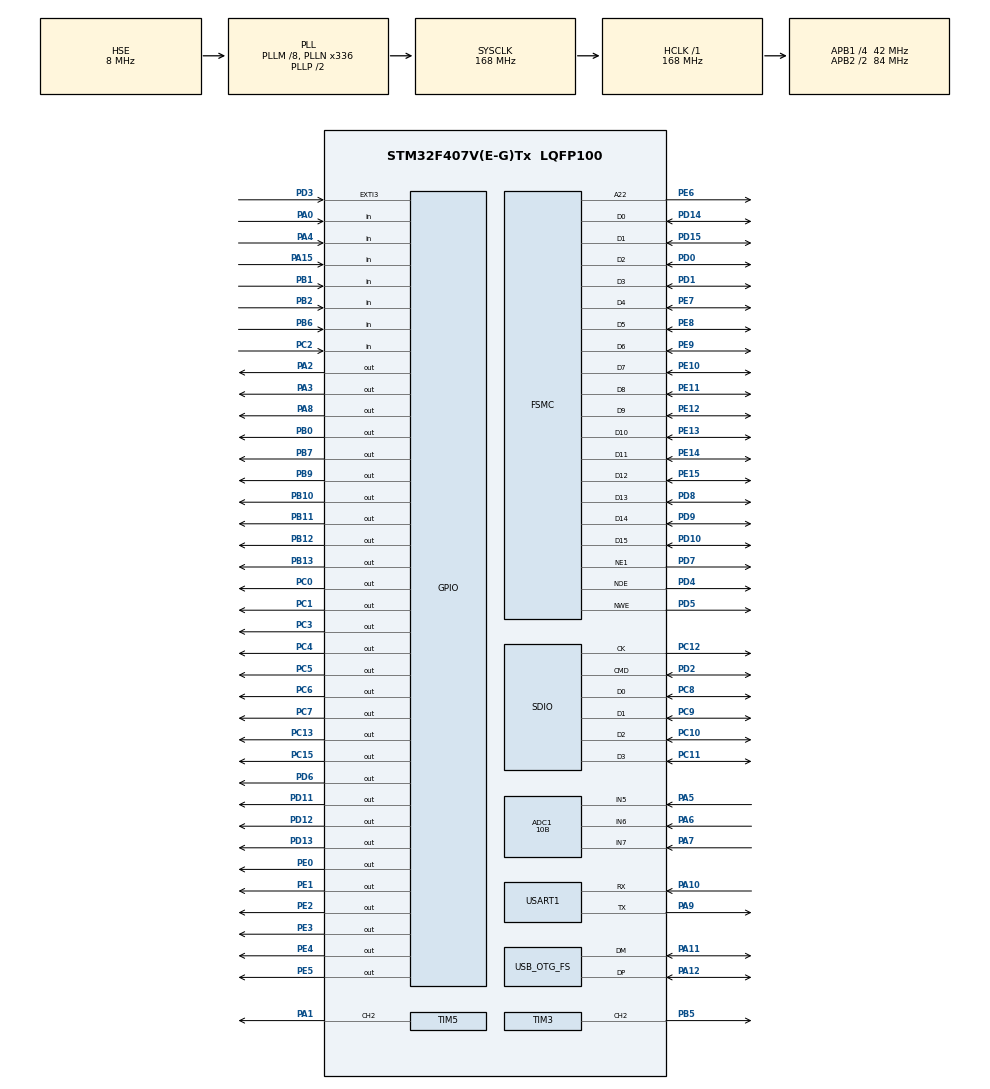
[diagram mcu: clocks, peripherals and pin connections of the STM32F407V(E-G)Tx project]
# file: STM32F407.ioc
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ADC1.Channel-0\#ChannelRegularConversion=ADC_CHANNEL_7
ADC1.ClockPrescaler=ADC_CLOCK_SYNC_PCLK_DIV4
ADC1.ContinuousConvMode=DISABLE
ADC1.DMAContinuousRequests=DISABLE
ADC1.DataAlign=ADC_DATAALIGN_RIGHT
ADC1.DiscontinuousConvMode=DISABLE
ADC1.EOCSelection=ADC_EOC_SINGLE_CONV
ADC1.EnableAnalogWatchDog=false
ADC1.ExternalTrigConvEdge=ADC_EXTERNALTRIGCONVEDGE_NONE
ADC1.InjNumberOfConversion=0
ADC1.NbrOfConversion=1
ADC1.NbrOfConversionFlag=1
ADC1.Rank-0\#ChannelRegularConversion=1
ADC1.Resolution=ADC_RESOLUTION_10B
ADC1.SamplingTime-0\#ChannelRegularConversion=ADC_SAMPLETIME_3CYCLES
ADC1.ScanConvMode=ENABLE
ADC1.master=1
Dma.Request0=USART1_RX
Dma.Request1=USART1_TX
Dma.Request2=SDIO_RX
Dma.Request3=SDIO_TX
Dma.SDIO_RX.2.Direction=DMA_PERIPH_TO_MEMORY
Dma.SDIO_RX.2.FIFOMode=DMA_FIFOMODE_ENABLE
Dma.SDIO_RX.2.FIFOThreshold=DMA_FIFO_THRESHOLD_FULL
Dma.SDIO_RX.2.Instance=DMA2_Stream3
Dma.SDIO_RX.2.MemBurst=DMA_MBURST_INC4
Dma.SDIO_RX.2.MemDataAlignment=DMA_MDATAALIGN_WORD
Dma.SDIO_RX.2.MemInc=DMA_MINC_ENABLE
Dma.SDIO_RX.2.Mode=DMA_PFCTRL
Dma.SDIO_RX.2.PeriphBurst=DMA_PBURST_INC4
Dma.SDIO_RX.2.PeriphDataAlignment=DMA_PDATAALIGN_WORD
Dma.SDIO_RX.2.PeriphInc=DMA_PINC_DISABLE
Dma.SDIO_RX.2.Priority=DMA_PRIORITY_LOW
Dma.SDIO_TX.3.Direction=DMA_MEMORY_TO_PERIPH
Dma.SDIO_TX.3.FIFOMode=DMA_FIFOMODE_ENABLE
Dma.SDIO_TX.3.FIFOThreshold=DMA_FIFO_THRESHOLD_FULL
Dma.SDIO_TX.3.Instance=DMA2_Stream6
Dma.SDIO_TX.3.MemBurst=DMA_MBURST_INC4
Dma.SDIO_TX.3.MemDataAlignment=DMA_MDATAALIGN_WORD
Dma.SDIO_TX.3.MemInc=DMA_MINC_ENABLE
Dma.SDIO_TX.3.Mode=DMA_PFCTRL
Dma.SDIO_TX.3.PeriphBurst=DMA_PBURST_INC4
Dma.SDIO_TX.3.PeriphDataAlignment=DMA_PDATAALIGN_WORD
Dma.SDIO_TX.3.PeriphInc=DMA_PINC_DISABLE
Dma.SDIO_TX.3.Priority=DMA_PRIORITY_LOW
Dma.USART1_RX.0.Direction=DMA_PERIPH_TO_MEMORY
Dma.USART1_RX.0.FIFOMode=DMA_FIFOMODE_DISABLE
Dma.USART1_RX.0.Instance=DMA2_Stream5
Dma.USART1_RX.0.MemDataAlignment=DMA_MDATAALIGN_BYTE
Dma.USART1_RX.0.MemInc=DMA_MINC_ENABLE
Dma.USART1_RX.0.Mode=DMA_CIRCULAR
Dma.USART1_RX.0.PeriphDataAlignment=DMA_PDATAALIGN_BYTE
Dma.USART1_RX.0.PeriphInc=DMA_PINC_DISABLE
Dma.USART1_RX.0.Priority=DMA_PRIORITY_LOW
Dma.USART1_TX.1.Direction=DMA_MEMORY_TO_PERIPH
Dma.USART1_TX.1.FIFOMode=DMA_FIFOMODE_DISABLE
Dma.USART1_TX.1.Instance=DMA2_Stream7
Dma.USART1_TX.1.MemDataAlignment=DMA_MDATAALIGN_BYTE
Dma.USART1_TX.1.MemInc=DMA_MINC_ENABLE
Dma.USART1_TX.1.Mode=DMA_CIRCULAR
Dma.USART1_TX.1.PeriphDataAlignment=DMA_PDATAALIGN_BYTE
Dma.USART1_TX.1.PeriphInc=DMA_PINC_DISABLE
Dma.USART1_TX.1.Priority=DMA_PRIORITY_LOW
FATFS.BSP.number=1
FATFS._CODE_PAGE=936
FATFS._FS_LOCK=16
FATFS._MAX_LFN=128
FATFS._MAX_SS=512
FATFS._USE_LFN=3
FATFS._USE_TRIM=0
FATFS0.BSP.STBoard=false
FATFS0.BSP.api=UnknownBspDriver
FATFS0.BSP.i2caddr=0
FATFS0.BSP.i2creg=0
FATFS0.BSP.instance=PB6
FATFS0.BSP.ip=GPIO
FATFS0.BSP.mode=Input
FATFS0.BSP.name=Detect_SDIO
FATFS0.BSP.solution=PB6
FREERTOS.CountingSemaphores01=GUISendSem,2,Dynamic,NULL;GUIWaitSem,2,Dynamic,NULL;ReadUdiskSem,2,Dynamic,NULL;ReceiveUartCmd,2,Dynamic,NULL
FREERTOS.HEAP_NUMBER=4
FREERTOS.INCLUDE_uxTaskGetStackHighWaterMark=1
FREERTOS.Queues01=GcodeCommand,32,uint32_t,0,Dynamic,NULL,NULL
FREERTOS.Tasks01=InitTask,3,1024,InitTask_OS,Default,NULL,Dynamic,NULL,NULL;RefDataTask,2,1024,RefDataTask_OS,Default,NULL,Dynamic,NULL,NULL;ReadUdiskTask,2,1024,ReadUdiskTask_OS,Default,NULL,Dynamic,NULL,NULL;PrintTask,2,1024,PrintTask_OS,Default,NULL,Dynamic,NULL,NULL;GUITask,0,1024,GUITask_OS,Default,NULL,Dynamic,NULL,NULL;RespondGUITask,0,1024,RespondGUITask_OS,Default,NULL,Dynamic,NULL,NULL
FREERTOS.configGENERATE_RUN_TIME_STATS=0
FREERTOS.configLIBRARY_MAX_SYSCALL_INTERRUPT_PRIORITY=5
FREERTOS.configMAX_PRIORITIES=7
FREERTOS.configMINIMAL_STACK_SIZE=128
FREERTOS.configTOTAL_HEAP_SIZE=32768
FREERTOS.configUSE_COUNTING_SEMAPHORES=1
FREERTOS.configUSE_RECURSIVE_MUTEXES=1
FREERTOS.configUSE_STATS_FORMATTING_FUNCTIONS=0
FREERTOS.configUSE_TICKLESS_IDLE=0
FREERTOS.configUSE_TRACE_FACILITY=1
FSMC.BusTurnAroundDuration1=0
FSMC.DataSetupTime1=60
FSMC.ExtendedAddressSetupTime1=9
FSMC.ExtendedBusTurnAroundDuration1=0
FSMC.ExtendedDataSetupTime1=8
FSMC.ExtendedMode1=FSMC_EXTENDED_MODE_ENABLE
IWDG.Prescaler=IWDG_PRESCALER_64
IWDG.Reload=3125
Mcu.Family=STM32F4
Mcu.Name=STM32F407V(E-G)Tx
Mcu.Package=LQFP100
NVIC.ADC_IRQn=true\:6\:0\:true\:false\:true\:true\:true
NVIC.DMA2_Stream3_IRQn=true\:5\:0\:true\:false\:true\:true\:true
NVIC.DMA2_Stream5_IRQn=true\:7\:0\:true\:false\:true\:true\:true
NVIC.DMA2_Stream6_IRQn=true\:5\:0\:true\:false\:true\:true\:true
NVIC.DMA2_Stream7_IRQn=true\:7\:0\:true\:false\:true\:true\:true
NVIC.EXTI3_IRQn=true\:5\:0\:true\:false\:true\:true\:true
NVIC.OTG_FS_IRQn=true\:5\:0\:true\:false\:true\:true\:true
NVIC.PriorityGroup=NVIC_PRIORITYGROUP_4
NVIC.SDIO_IRQn=true\:5\:0\:true\:false\:true\:true\:true
NVIC.TIM1_UP_TIM10_IRQn=true\:0\:0\:false\:false\:true\:false\:true
NVIC.TIM2_IRQn=true\:7\:0\:true\:false\:true\:true\:true
NVIC.TIM3_IRQn=true\:7\:0\:true\:false\:true\:true\:true
NVIC.TIM4_IRQn=true\:5\:0\:true\:false\:true\:false\:true
NVIC.TIM5_IRQn=true\:7\:0\:true\:false\:true\:true\:true
NVIC.TIM6_DAC_IRQn=true\:5\:0\:true\:false\:true\:true\:true
NVIC.TIM7_IRQn=true\:7\:0\:true\:false\:true\:true\:true
NVIC.TimeBase=TIM1_UP_TIM10_IRQn
NVIC.TimeBaseIP=TIM1
NVIC.USART1_IRQn=true\:7\:0\:true\:false\:true\:true\:true
PA0-WKUP.GPIO_Mode=GPIO_MODE_INPUT
PA0-WKUP.GPIO_PuPd=GPIO_PULLUP
PA0-WKUP.Signal=GPIO_Input
PA1.Signal=S_TIM5_CH2
PA10.Mode=Asynchronous
PA10.Signal=USART1_RX
PA11.GPIO_PuPd=GPIO_NOPULL
PA11.GPIO_Speed=GPIO_SPEED_FREQ_MEDIUM
PA11.Mode=Host_Only
PA11.Signal=USB_OTG_FS_DM
PA12.GPIO_PuPd=GPIO_NOPULL
PA12.GPIO_Speed=GPIO_SPEED_FREQ_MEDIUM
PA12.Mode=Host_Only
PA12.Signal=USB_OTG_FS_DP
PA15.GPIO_Mode=GPIO_MODE_INPUT
PA15.GPIO_PuPd=GPIO_PULLUP
PA15.Signal=GPIO_Input
PA2.Signal=GPIO_Output
PA3.Signal=GPIO_Output
PA4.GPIO_Mode=GPIO_MODE_INPUT
PA4.GPIO_PuPd=GPIO_PULLUP
PA4.Signal=GPIO_Input
PA5.Signal=ADCx_IN5
PA6.Signal=ADCx_IN6
PA7.Signal=ADCx_IN7
PA8.Signal=GPIO_Output
PA9.Mode=Asynchronous
PA9.Signal=USART1_TX
PB0.Signal=GPIO_Output
PB1.Signal=GPIO_Input
PB10.Signal=GPIO_Output
PB11.Signal=GPIO_Output
PB12.Signal=GPIO_Output
PB13.Signal=GPIO_Output
PB2.Signal=GPIO_Input
PB5.Signal=S_TIM3_CH2
PB6.GPIO_Mode=GPIO_MODE_INPUT
PB6.GPIO_PuPd=GPIO_PULLUP
PB6.Signal=GPIO_Input
PB7.Signal=GPIO_Output
PB9.Signal=GPIO_Output
PC0.Signal=GPIO_Output
PC1.Signal=GPIO_Output
PC10.GPIO_Mode=GPIO_MODE_AF_PP
PC10.GPIO_PuPd=GPIO_PULLUP
PC10.GPIO_Speed_High_Default=GPIO_SPEED_FREQ_LOW
PC10.Mode=SD_4_bits_Wide_bus
PC10.Signal=SDIO_D2
PC11.GPIO_Mode=GPIO_MODE_AF_PP
PC11.GPIO_PuPd=GPIO_PULLUP
PC11.GPIO_Speed_High_Default=GPIO_SPEED_FREQ_LOW
PC11.Mode=SD_4_bits_Wide_bus
PC11.Signal=SDIO_D3
PC12.GPIO_Mode=GPIO_MODE_AF_PP
PC12.GPIO_PuPd=GPIO_NOPULL
PC12.GPIO_Speed_High_Default=GPIO_SPEED_FREQ_LOW
PC12.Mode=SD_4_bits_Wide_bus
PC12.Signal=SDIO_CK
PC13-ANTI_TAMP.Signal=GPIO_Output
PC15-OSC32_OUT.Signal=GPIO_Output
PC2.GPIO_Mode=GPIO_MODE_INPUT
PC2.GPIO_PuPd=GPIO_PULLUP
PC2.Signal=GPIO_Input
PC3.Signal=GPIO_Output
PC4.Signal=GPIO_Output
PC5.Signal=GPIO_Output
PC6.Signal=GPIO_Output
PC7.Signal=GPIO_Output
PC8.GPIO_Mode=GPIO_MODE_AF_PP
PC8.GPIO_PuPd=GPIO_PULLUP
PC8.GPIO_Speed_High_Default=GPIO_SPEED_FREQ_LOW
PC8.Mode=SD_4_bits_Wide_bus
PC8.Signal=SDIO_D0
PC9.GPIO_Mode=GPIO_MODE_AF_PP
PC9.GPIO_PuPd=GPIO_PULLUP
PC9.GPIO_Speed_High_Default=GPIO_SPEED_FREQ_LOW
PC9.Mode=SD_4_bits_Wide_bus
PC9.Signal=SDIO_D1
PD0.GPIO_Mode=GPIO_MODE_AF_PP
PD0.GPIO_PuPd=GPIO_PULLUP
PD0.GPIO_Speed_High_Default=GPIO_SPEED_FREQ_LOW
PD0.Mode=16b-d1
PD0.Signal=FSMC_D2
PD1.GPIO_Mode=GPIO_MODE_AF_PP
PD1.GPIO_PuPd=GPIO_PULLUP
PD1.GPIO_Speed_High_Default=GPIO_SPEED_FREQ_LOW
PD1.Mode=16b-d1
PD1.Signal=FSMC_D3
PD10.GPIO_Mode=GPIO_MODE_AF_PP
PD10.GPIO_PuPd=GPIO_PULLUP
PD10.GPIO_Speed_High_Default=GPIO_SPEED_FREQ_LOW
PD10.Mode=16b-d1
PD10.Signal=FSMC_D15
PD11.Signal=GPIO_Output
PD12.Signal=GPIO_Output
PD13.GPIO_ModeDefaultOutputPP=GPIO_MODE_OUTPUT_PP
PD13.GPIO_PuPd=GPIO_NOPULL
PD13.GPIO_Speed=GPIO_SPEED_FREQ_LOW
PD13.Signal=GPIO_Output
PD14.GPIO_Mode=GPIO_MODE_AF_PP
PD14.GPIO_PuPd=GPIO_PULLUP
PD14.GPIO_Speed_High_Default=GPIO_SPEED_FREQ_LOW
PD14.Mode=16b-d1
PD14.Signal=FSMC_D0
PD15.GPIO_Mode=GPIO_MODE_AF_PP
PD15.GPIO_PuPd=GPIO_PULLUP
PD15.GPIO_Speed_High_Default=GPIO_SPEED_FREQ_LOW
PD15.Mode=16b-d1
PD15.Signal=FSMC_D1
PD2.GPIO_Mode=GPIO_MODE_AF_PP
PD2.GPIO_PuPd=GPIO_PULLUP
PD2.GPIO_Speed_High_Default=GPIO_SPEED_FREQ_LOW
PD2.Mode=SD_4_bits_Wide_bus
PD2.Signal=SDIO_CMD
PD3.GPIO_ModeDefaultEXTI=GPIO_MODE_IT_FALLING
PD3.GPIO_PuPd=GPIO_PULLUP
PD3.Signal=GPXTI3
PD4.GPIO_Mode=GPIO_MODE_AF_PP
PD4.GPIO_PuPd=GPIO_PULLUP
PD4.GPIO_Speed_High_Default=GPIO_SPEED_FREQ_LOW
PD4.Mode=Lcd1
PD4.Signal=FSMC_NOE
PD5.GPIO_Mode=GPIO_MODE_AF_PP
PD5.GPIO_PuPd=GPIO_PULLUP
PD5.GPIO_Speed_High_Default=GPIO_SPEED_FREQ_LOW
PD5.Mode=Lcd1
PD5.Signal=FSMC_NWE
PD6.Signal=GPIO_Output
PD7.GPIO_Mode=GPIO_MODE_AF_PP
PD7.GPIO_PuPd=GPIO_PULLUP
PD7.GPIO_Speed_High_Default=GPIO_SPEED_FREQ_LOW
PD7.Mode=NorPsramChipSelect1_1
PD7.Signal=FSMC_NE1
PD8.GPIO_Mode=GPIO_MODE_AF_PP
PD8.GPIO_PuPd=GPIO_PULLUP
PD8.GPIO_Speed_High_Default=GPIO_SPEED_FREQ_LOW
PD8.Mode=16b-d1
PD8.Signal=FSMC_D13
PD9.GPIO_Mode=GPIO_MODE_AF_PP
PD9.GPIO_PuPd=GPIO_PULLUP
PD9.GPIO_Speed_High_Default=GPIO_SPEED_FREQ_LOW
PD9.Mode=16b-d1
PD9.Signal=FSMC_D14
PE0.Signal=GPIO_Output
PE1.Signal=GPIO_Output
PE10.GPIO_Mode=GPIO_MODE_AF_PP
PE10.GPIO_PuPd=GPIO_PULLUP
PE10.GPIO_Speed_High_Default=GPIO_SPEED_FREQ_LOW
PE10.Mode=16b-d1
PE10.Signal=FSMC_D7
PE11.GPIO_Mode=GPIO_MODE_AF_PP
PE11.GPIO_PuPd=GPIO_PULLUP
PE11.GPIO_Speed_High_Default=GPIO_SPEED_FREQ_LOW
PE11.Mode=16b-d1
PE11.Signal=FSMC_D8
PE12.GPIO_Mode=GPIO_MODE_AF_PP
PE12.GPIO_PuPd=GPIO_PULLUP
PE12.GPIO_Speed_High_Default=GPIO_SPEED_FREQ_LOW
PE12.Mode=16b-d1
PE12.Signal=FSMC_D9
PE13.GPIO_Mode=GPIO_MODE_AF_PP
PE13.GPIO_PuPd=GPIO_PULLUP
PE13.GPIO_Speed_High_Default=GPIO_SPEED_FREQ_LOW
PE13.Mode=16b-d1
PE13.Signal=FSMC_D10
PE14.GPIO_Mode=GPIO_MODE_AF_PP
PE14.GPIO_PuPd=GPIO_PULLUP
PE14.GPIO_Speed_High_Default=GPIO_SPEED_FREQ_LOW
PE14.Mode=16b-d1
PE14.Signal=FSMC_D11
PE15.GPIO_Mode=GPIO_MODE_AF_PP
PE15.GPIO_PuPd=GPIO_PULLUP
PE15.GPIO_Speed_High_Default=GPIO_SPEED_FREQ_LOW
PE15.Mode=16b-d1
PE15.Signal=FSMC_D12
PE2.Signal=GPIO_Output
PE3.Signal=GPIO_Output
PE4.Signal=GPIO_Output
PE5.Signal=GPIO_Output
PE6.GPIO_Mode=GPIO_MODE_AF_PP
PE6.GPIO_PuPd=GPIO_PULLUP
PE6.GPIO_Speed_High_Default=GPIO_SPEED_FREQ_LOW
PE6.Mode=A22_1
PE6.Signal=FSMC_A22
PE7.GPIO_Mode=GPIO_MODE_AF_PP
PE7.GPIO_PuPd=GPIO_PULLUP
PE7.GPIO_Speed_High_Default=GPIO_SPEED_FREQ_LOW
PE7.Mode=16b-d1
PE7.Signal=FSMC_D4
PE8.GPIO_Mode=GPIO_MODE_AF_PP
PE8.GPIO_PuPd=GPIO_PULLUP
PE8.GPIO_Speed_High_Default=GPIO_SPEED_FREQ_LOW
PE8.Mode=16b-d1
PE8.Signal=FSMC_D5
PE9.GPIO_Mode=GPIO_MODE_AF_PP
PE9.GPIO_PuPd=GPIO_PULLUP
PE9.GPIO_Speed_High_Default=GPIO_SPEED_FREQ_LOW
PE9.Mode=16b-d1
PE9.Signal=FSMC_D6
PH0-OSC_IN.Mode=HSE-External-Oscillator
PH0-OSC_IN.Signal=RCC_OSC_IN
PH1-OSC_OUT.Mode=HSE-External-Oscillator
PH1-OSC_OUT.Signal=RCC_OSC_OUT
ProjectManager.HeapSize=0x2400
ProjectManager.StackSize=0x2400
ProjectManager.TargetToolchain=MDK-ARM V5
RCC.48MHZClocksFreq_Value=48000000
RCC.AHBFreq_Value=168000000
RCC.APB1CLKDivider=RCC_HCLK_DIV4
RCC.APB1Freq_Value=42000000
RCC.APB1TimFreq_Value=84000000
RCC.APB2CLKDivider=RCC_HCLK_DIV2
RCC.APB2Freq_Value=84000000
RCC.APB2TimFreq_Value=168000000
RCC.CortexFreq_Value=21000000
RCC.Cortex_Div=SYSTICK_CLKSOURCE_HCLK_DIV8
RCC.HCLKFreq_Value=168000000
RCC.HSE_VALUE=8000000
RCC.HSI_VALUE=16000000
RCC.LSE_VALUE=32768
RCC.PLLM=8
RCC.PLLN=336
RCC.PLLQ=7
RCC.SYSCLKFreq_VALUE=168000000
RCC.SYSCLKSource=RCC_SYSCLKSOURCE_PLLCLK
RCC.VCOOutputFreq_Value=336000000
SDIO.ClockDiv=22
SH.ADCx_IN5.0=ADC1_IN5,IN5
SH.ADCx_IN6.0=ADC1_IN6,IN6
SH.ADCx_IN7.0=ADC1_IN7,IN7
SH.S_TIM3_CH2.0=TIM3_CH2,PWM Generation2 CH2
SH.S_TIM5_CH2.0=TIM5_CH2,PWM Generation2 CH2
TIM2.Period=1999
TIM2.Prescaler=83
TIM3.Channel-PWM\ Generation2\ CH2=TIM_CHANNEL_2
TIM3.OCPolarity_2=TIM_OCPOLARITY_LOW
TIM3.Period=999
TIM3.Prescaler=167
TIM3.Pulse-PWM\ Generation2\ CH2=999
TIM4.Period=16383
TIM4.Prescaler=41
TIM5.Channel-PWM\ Generation2\ CH2=TIM_CHANNEL_2
TIM5.Period=999
TIM5.Prescaler=83
TIM6.Period=999
TIM6.Prescaler=83
TIM7.Period=9
TIM7.Prescaler=41
USART1.VirtualMode=VM_ASYNC
USB_HOST.USBH_HandleTypeDef-MSC_FS=hUsbHostFS
USB_HOST.USBH_MAX_SIZE_CONFIGURATION-MSC_FS=512
USB_HOST.USBH_PROCESS_PRIO-MSC_FS=osPriorityHigh
USB_HOST.USBH_PROCESS_STACK_SIZE-MSC_FS=1024
USB_HOST.VirtualModeFS=Msc
USB_OTG_FS.VirtualMode=Host_Only
USB_OTG_FS.phy_itface=HCD_PHY_EMBEDDED
VP_FATFS_VS_SDIO.Mode=SDIO
VP_FATFS_VS_USB.Mode=USB
VP_FREERTOS_VS_ENABLE.Mode=Enabled
VP_IWDG_VS_IWDG.Mode=IWDG_Activate
VP_SYS_VS_tim1.Mode=TIM1
VP_TIM2_VS_ClockSourceINT.Mode=Internal
VP_TIM3_VS_ClockSourceINT.Mode=Internal
VP_TIM4_VS_ClockSourceINT.Mode=Internal
VP_TIM5_VS_ClockSourceINT.Mode=Internal
VP_TIM6_VS_ClockSourceINT.Mode=Enable_Timer
VP_TIM7_VS_ClockSourceINT.Mode=Enable_Timer
VP_USB_HOST_VS_USB_HOST_MSC_FS.Mode=MSC_FS
board=APP2

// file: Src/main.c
/* USER CODE BEGIN Header */
/**
  ******************************************************************************
  * @file           : main.c
  * @brief          : Main program body
  ******************************************************************************
  * This notice applies to any and all portions of this file
  * that are not between comment pairs USER CODE BEGIN and
  * USER CODE END. Other portions of this file, whether
  * inserted by the user or by software development tools
  * are owned by their respective copyright owners.
  *
  * Copyright (c) 2020 STMicroelectronics International N.V.
  * All rights reserved.
  *
  * Redistribution and use in source and binary forms, with or without
  * modification, are permitted, provided that the following conditions are met:
  *
  * 1. Redistribution of source code must retain the above copyright notice,
  *    this list of conditions and the following disclaimer.
  * 2. Redistributions in binary form must reproduce the above copyright notice,
  *    this list of conditions and the following disclaimer in the documentation
  *    and/or other materials provided with the distribution.
  * 3. Neither the name of STMicroelectronics nor the names of other
  *    contributors to this software may be used to endorse or promote products
  *    derived from this software without specific written permission.
  * 4. This software, including modifications and/or derivative works of this
  *    software, must execute solely and exclusively on microcontroller or
  *    microprocessor devices manufactured by or for STMicroelectronics.
  * 5. Redistribution and use of this software other than as permitted under
  *    this license is void and will automatically terminate your rights under
  *    this license.
  *
  * THIS SOFTWARE IS PROVIDED BY STMICROELECTRONICS AND CONTRIBUTORS "AS IS"
  * AND ANY EXPRESS, IMPLIED OR STATUTORY WARRANTIES, INCLUDING, BUT NOT
  * LIMITED TO, THE IMPLIED WARRANTIES OF MERCHANTABILITY, FITNESS FOR A
  * PARTICULAR PURPOSE AND NON-INFRINGEMENT OF THIRD PARTY INTELLECTUAL PROPERTY
  * RIGHTS ARE DISCLAIMED TO THE FULLEST EXTENT PERMITTED BY LAW. IN NO EVENT
  * SHALL STMICROELECTRONICS OR CONTRIBUTORS BE LIABLE FOR ANY DIRECT, INDIRECT,
  * INCIDENTAL, SPECIAL, EXEMPLARY, OR CONSEQUENTIAL DAMAGES (INCLUDING, BUT NOT
  * LIMITED TO, PROCUREMENT OF SUBSTITUTE GOODS OR SERVICES; LOSS OF USE, DATA,
  * OR PROFITS; OR BUSINESS INTERRUPTION) HOWEVER CAUSED AND ON ANY THEORY OF
  * LIABILITY, WHETHER IN CONTRACT, STRICT LIABILITY, OR TORT (INCLUDING
  * NEGLIGENCE OR OTHERWISE) ARISING IN ANY WAY OUT OF THE USE OF THIS SOFTWARE,
  * EVEN IF ADVISED OF THE POSSIBILITY OF SUCH DAMAGE.
  *
  ******************************************************************************
  */
/* USER CODE END Header */

#include "main.h"
#include "cmsis_os.h"
#include "fatfs.h"
#include "usb_host.h"

/* USER CODE BEGIN Includes */
#include "controlfunction.h"

#include "ref_data_task.h"
#include "respond_gui_task.h"
#include "gui_task.h"
#include "start_default_task.h"
#include "print_task.h"
#include "read_udisk_task.h"
#include "user_interface.h"
#include "Alter.h"
/* USER CODE END Includes */

ADC_HandleTypeDef hadc1;

IWDG_HandleTypeDef hiwdg;

SD_HandleTypeDef hsd;
DMA_HandleTypeDef hdma_sdio_rx;
DMA_HandleTypeDef hdma_sdio_tx;

TIM_HandleTypeDef htim2;
TIM_HandleTypeDef htim3;
TIM_HandleTypeDef htim4;
TIM_HandleTypeDef htim5;
TIM_HandleTypeDef htim6;
TIM_HandleTypeDef htim7;

UART_HandleTypeDef huart1;
DMA_HandleTypeDef hdma_usart1_rx;
DMA_HandleTypeDef hdma_usart1_tx;

SRAM_HandleTypeDef hsram1;

osThreadId InitTaskHandle;
osThreadId RefDataTaskHandle;
osThreadId ReadUdiskTaskHandle;
osThreadId PrintTaskHandle;
osThreadId GUITaskHandle;
osThreadId RespondGUITaskHandle;
osMessageQId GcodeCommandHandle;
osSemaphoreId GUISendSemHandle;
osSemaphoreId GUIWaitSemHandle;
osSemaphoreId ReadUdiskSemHandle;
osSemaphoreId ReceiveUartCmdHandle;
/* USER CODE BEGIN PV */

static volatile bool is_start_default_task_init = false;
/* USER CODE END PV */

void SystemClock_Config(void);
static void MX_GPIO_Init(void);
static void MX_DMA_Init(void);
static void MX_ADC1_Init(void);
static void MX_FSMC_Init(void);
static void MX_IWDG_Init(void);
static void MX_SDIO_SD_Init(void);
static void MX_TIM3_Init(void);
static void MX_TIM4_Init(void);
static void MX_TIM5_Init(void);
static void MX_USART1_UART_Init(void);
static void MX_TIM2_Init(void);
static void MX_TIM6_Init(void);
static void MX_TIM7_Init(void);
void InitTask_OS(void const * argument);
void RefDataTask_OS(void const * argument);
void ReadUdiskTask_OS(void const * argument);
void PrintTask_OS(void const * argument);
void GUITask_OS(void const * argument);
void RespondGUITask_OS(void const * argument);

int main(void)
{
  /* USER CODE BEGIN 1 */
  main_user_core1_init();
  /* USER CODE END 1 */

  /* MCU Configuration--------------------------------------------------------*/

  /* Reset of all peripherals, Initializes the Flash interface and the Systick. */
  HAL_Init();

  /* Configure the system clock */
  SystemClock_Config();

  /* Initialize all configured peripherals */
  MX_GPIO_Init();
  MX_DMA_Init();
  MX_ADC1_Init();
  MX_FSMC_Init();
  MX_IWDG_Init();
  MX_SDIO_SD_Init();
  MX_TIM3_Init();
  MX_TIM4_Init();
  MX_TIM5_Init();
  MX_USART1_UART_Init();
  MX_TIM2_Init();
  MX_TIM6_Init();
  MX_TIM7_Init();
  /* USER CODE BEGIN 2 */

//  MX_TIM3_Init2();
  //屏幕BL频率是1kHz
  HAL_TIM_PWM_Start(&htim3,TIM_CHANNEL_2);//开启PWM通道4
  Fan_5v_Init();
  main_user_core2_init();
  /* USER CODE END 2 */

  /* Create the semaphores(s) */
  /* definition and creation of GUISendSem */
  osSemaphoreDef(GUISendSem);
  GUISendSemHandle = osSemaphoreCreate(osSemaphore(GUISendSem), 2);

  /* definition and creation of GUIWaitSem */
  osSemaphoreDef(GUIWaitSem);
  GUIWaitSemHandle = osSemaphoreCreate(osSemaphore(GUIWaitSem), 2);

  /* definition and creation of ReadUdiskSem */
  osSemaphoreDef(ReadUdiskSem);
  ReadUdiskSemHandle = osSemaphoreCreate(osSemaphore(ReadUdiskSem), 2);

  /* definition and creation of ReceiveUartCmd */
  osSemaphoreDef(ReceiveUartCmd);
  ReceiveUartCmdHandle = osSemaphoreCreate(osSemaphore(ReceiveUartCmd), 2);

  /* Create the thread(s) */
  /* definition and creation of InitTask */
  osThreadDef(InitTask, InitTask_OS, osPriorityRealtime, 0, 1024);
  InitTaskHandle = osThreadCreate(osThread(InitTask), NULL);

  /* definition and creation of RefDataTask */
  osThreadDef(RefDataTask, RefDataTask_OS, osPriorityHigh, 0, 1024);
  RefDataTaskHandle = osThreadCreate(osThread(RefDataTask), NULL);

  /* definition and creation of ReadUdiskTask */
  osThreadDef(ReadUdiskTask, ReadUdiskTask_OS, osPriorityHigh, 0, 1024);
  ReadUdiskTaskHandle = osThreadCreate(osThread(ReadUdiskTask), NULL);

  /* definition and creation of PrintTask */
  osThreadDef(PrintTask, PrintTask_OS, osPriorityHigh, 0, 1024);
  PrintTaskHandle = osThreadCreate(osThread(PrintTask), NULL);

  /* definition and creation of GUITask */
  osThreadDef(GUITask, GUITask_OS, osPriorityNormal, 0, 1024);
  GUITaskHandle = osThreadCreate(osThread(GUITask), NULL);

  /* definition and creation of RespondGUITask */
  osThreadDef(RespondGUITask, RespondGUITask_OS, osPriorityNormal, 0, 1024);
  RespondGUITaskHandle = osThreadCreate(osThread(RespondGUITask), NULL);

  /* Create the queue(s) */
  /* definition and creation of GcodeCommand */
  osMessageQDef(GcodeCommand, 32, uint32_t);
  GcodeCommandHandle = osMessageCreate(osMessageQ(GcodeCommand), NULL);

  /* Start scheduler */
  osKernelStart();

  /* We should never get here as control is now taken by the scheduler */

  /* Infinite loop */
  while (1)
  {

  }
}

void SystemClock_Config(void)
{
  RCC_OscInitTypeDef RCC_OscInitStruct = {0};
  RCC_ClkInitTypeDef RCC_ClkInitStruct = {0};

  /**Configure the main internal regulator output voltage
  */
  __HAL_RCC_PWR_CLK_ENABLE();
  __HAL_PWR_VOLTAGESCALING_CONFIG(PWR_REGULATOR_VOLTAGE_SCALE1);
  /**Initializes the CPU, AHB and APB busses clocks
  */
  RCC_OscInitStruct.OscillatorType = RCC_OSCILLATORTYPE_LSI|RCC_OSCILLATORTYPE_HSE;
  RCC_OscInitStruct.HSEState = RCC_HSE_ON;
  RCC_OscInitStruct.LSIState = RCC_LSI_ON;
  RCC_OscInitStruct.PLL.PLLState = RCC_PLL_ON;
  RCC_OscInitStruct.PLL.PLLSource = RCC_PLLSOURCE_HSE;
  RCC_OscInitStruct.PLL.PLLM = 8;
  RCC_OscInitStruct.PLL.PLLN = 336;
  RCC_OscInitStruct.PLL.PLLP = RCC_PLLP_DIV2;
  RCC_OscInitStruct.PLL.PLLQ = 7;
  if (HAL_RCC_OscConfig(&RCC_OscInitStruct) != HAL_OK)
  {
    Error_Handler();
  }
  /**Initializes the CPU, AHB and APB busses clocks
  */
  RCC_ClkInitStruct.ClockType = RCC_CLOCKTYPE_HCLK|RCC_CLOCKTYPE_SYSCLK
                              |RCC_CLOCKTYPE_PCLK1|RCC_CLOCKTYPE_PCLK2;
  RCC_ClkInitStruct.SYSCLKSource = RCC_SYSCLKSOURCE_PLLCLK;
  RCC_ClkInitStruct.AHBCLKDivider = RCC_SYSCLK_DIV1;
  RCC_ClkInitStruct.APB1CLKDivider = RCC_HCLK_DIV4;
  RCC_ClkInitStruct.APB2CLKDivider = RCC_HCLK_DIV2;

  if (HAL_RCC_ClockConfig(&RCC_ClkInitStruct, FLASH_LATENCY_5) != HAL_OK)
  {
    Error_Handler();
  }
}

static void MX_ADC1_Init(void)
{

  ADC_ChannelConfTypeDef sConfig = {0};

  /**Configure the global features of the ADC (Clock, Resolution, Data Alignment and number of conversion)
  */
  hadc1.Instance = ADC1;
  hadc1.Init.ClockPrescaler = ADC_CLOCK_SYNC_PCLK_DIV4;
  hadc1.Init.Resolution = ADC_RESOLUTION_10B;
  hadc1.Init.ScanConvMode = ENABLE;
  hadc1.Init.ContinuousConvMode = DISABLE;
  hadc1.Init.DiscontinuousConvMode = DISABLE;
  hadc1.Init.ExternalTrigConvEdge = ADC_EXTERNALTRIGCONVEDGE_NONE;
  hadc1.Init.ExternalTrigConv = ADC_SOFTWARE_START;
  hadc1.Init.DataAlign = ADC_DATAALIGN_RIGHT;
  hadc1.Init.NbrOfConversion = 1;
  hadc1.Init.DMAContinuousRequests = DISABLE;
  hadc1.Init.EOCSelection = ADC_EOC_SINGLE_CONV;
  if (HAL_ADC_Init(&hadc1) != HAL_OK)
  {
    Error_Handler();
  }
  /**Configure for the selected ADC regular channel its corresponding rank in the sequencer and its sample time.
  */
  sConfig.Channel = ADC_CHANNEL_7;
  sConfig.Rank = 1;
  sConfig.SamplingTime = ADC_SAMPLETIME_3CYCLES;
  if (HAL_ADC_ConfigChannel(&hadc1, &sConfig) != HAL_OK)
  {
    Error_Handler();
  }

}

static void MX_IWDG_Init(void)
{

  hiwdg.Instance = IWDG;
  hiwdg.Init.Prescaler = IWDG_PRESCALER_64;
  hiwdg.Init.Reload = 3125;
  if (HAL_IWDG_Init(&hiwdg) != HAL_OK)
  {
    Error_Handler();
  }

}

static void MX_SDIO_SD_Init(void)
{

  hsd.Instance = SDIO;
  hsd.Init.ClockEdge = SDIO_CLOCK_EDGE_RISING;
  hsd.Init.ClockBypass = SDIO_CLOCK_BYPASS_DISABLE;
  hsd.Init.ClockPowerSave = SDIO_CLOCK_POWER_SAVE_DISABLE;
  hsd.Init.BusWide = SDIO_BUS_WIDE_1B;
  hsd.Init.HardwareFlowControl = SDIO_HARDWARE_FLOW_CONTROL_DISABLE;
  hsd.Init.ClockDiv = 22;

}

static void MX_TIM2_Init(void)
{

  TIM_ClockConfigTypeDef sClockSourceConfig = {0};
  TIM_MasterConfigTypeDef sMasterConfig = {0};

  htim2.Instance = TIM2;
  htim2.Init.Prescaler = 83;
  htim2.Init.CounterMode = TIM_COUNTERMODE_UP;
  htim2.Init.Period = 1999;
  htim2.Init.ClockDivision = TIM_CLOCKDIVISION_DIV1;
  if (HAL_TIM_Base_Init(&htim2) != HAL_OK)
  {
    Error_Handler();
  }
  sClockSourceConfig.ClockSource = TIM_CLOCKSOURCE_INTERNAL;
  if (HAL_TIM_ConfigClockSource(&htim2, &sClockSourceConfig) != HAL_OK)
  {
    Error_Handler();
  }
  sMasterConfig.MasterOutputTrigger = TIM_TRGO_RESET;
  sMasterConfig.MasterSlaveMode = TIM_MASTERSLAVEMODE_DISABLE;
  if (HAL_TIMEx_MasterConfigSynchronization(&htim2, &sMasterConfig) != HAL_OK)
  {
    Error_Handler();
  }

}

static void MX_TIM3_Init(void)
{

  TIM_ClockConfigTypeDef sClockSourceConfig = {0};
  TIM_MasterConfigTypeDef sMasterConfig = {0};
  TIM_OC_InitTypeDef sConfigOC = {0};

  htim3.Instance = TIM3;
  htim3.Init.Prescaler = 167;
  htim3.Init.CounterMode = TIM_COUNTERMODE_UP;
  htim3.Init.Period = 999;
  htim3.Init.ClockDivision = TIM_CLOCKDIVISION_DIV1;
  if (HAL_TIM_Base_Init(&htim3) != HAL_OK)
  {
    Error_Handler();
  }
  sClockSourceConfig.ClockSource = TIM_CLOCKSOURCE_INTERNAL;
  if (HAL_TIM_ConfigClockSource(&htim3, &sClockSourceConfig) != HAL_OK)
  {
    Error_Handler();
  }
  if (HAL_TIM_PWM_Init(&htim3) != HAL_OK)
  {
    Error_Handler();
  }
  sMasterConfig.MasterOutputTrigger = TIM_TRGO_RESET;
  sMasterConfig.MasterSlaveMode = TIM_MASTERSLAVEMODE_DISABLE;
  if (HAL_TIMEx_MasterConfigSynchronization(&htim3, &sMasterConfig) != HAL_OK)
  {
    Error_Handler();
  }
  sConfigOC.OCMode = TIM_OCMODE_PWM1;
  sConfigOC.Pulse = 999;
  sConfigOC.OCPolarity = TIM_OCPOLARITY_LOW;
  sConfigOC.OCFastMode = TIM_OCFAST_DISABLE;
  if (HAL_TIM_PWM_ConfigChannel(&htim3, &sConfigOC, TIM_CHANNEL_2) != HAL_OK)
  {
    Error_Handler();
  }
  HAL_TIM_MspPostInit(&htim3);

}

static void MX_TIM4_Init(void)
{

  TIM_ClockConfigTypeDef sClockSourceConfig = {0};
  TIM_MasterConfigTypeDef sMasterConfig = {0};

  htim4.Instance = TIM4;
  htim4.Init.Prescaler = 41;
  htim4.Init.CounterMode = TIM_COUNTERMODE_UP;
  htim4.Init.Period = 16383;
  htim4.Init.ClockDivision = TIM_CLOCKDIVISION_DIV1;
  if (HAL_TIM_Base_Init(&htim4) != HAL_OK)
  {
    Error_Handler();
  }
  sClockSourceConfig.ClockSource = TIM_CLOCKSOURCE_INTERNAL;
  if (HAL_TIM_ConfigClockSource(&htim4, &sClockSourceConfig) != HAL_OK)
  {
    Error_Handler();
  }
  sMasterConfig.MasterOutputTrigger = TIM_TRGO_RESET;
  sMasterConfig.MasterSlaveMode = TIM_MASTERSLAVEMODE_DISABLE;
  if (HAL_TIMEx_MasterConfigSynchronization(&htim4, &sMasterConfig) != HAL_OK)
  {
    Error_Handler();
  }

}

static void MX_TIM5_Init(void)
{

  TIM_ClockConfigTypeDef sClockSourceConfig = {0};
  TIM_MasterConfigTypeDef sMasterConfig = {0};
  TIM_OC_InitTypeDef sConfigOC = {0};

  htim5.Instance = TIM5;
  htim5.Init.Prescaler = 83;
  htim5.Init.CounterMode = TIM_COUNTERMODE_UP;
  htim5.Init.Period = 999;
  htim5.Init.ClockDivision = TIM_CLOCKDIVISION_DIV1;
  if (HAL_TIM_Base_Init(&htim5) != HAL_OK)
  {
    Error_Handler();
  }
  sClockSourceConfig.ClockSource = TIM_CLOCKSOURCE_INTERNAL;
  if (HAL_TIM_ConfigClockSource(&htim5, &sClockSourceConfig) != HAL_OK)
  {
    Error_Handler();
  }
  if (HAL_TIM_PWM_Init(&htim5) != HAL_OK)
  {
    Error_Handler();
  }
  sMasterConfig.MasterOutputTrigger = TIM_TRGO_RESET;
  sMasterConfig.MasterSlaveMode = TIM_MASTERSLAVEMODE_DISABLE;
  if (HAL_TIMEx_MasterConfigSynchronization(&htim5, &sMasterConfig) != HAL_OK)
  {
    Error_Handler();
  }
  sConfigOC.OCMode = TIM_OCMODE_PWM1;
  sConfigOC.Pulse = 0;
  sConfigOC.OCPolarity = TIM_OCPOLARITY_HIGH;
  sConfigOC.OCFastMode = TIM_OCFAST_DISABLE;
  if (HAL_TIM_PWM_ConfigChannel(&htim5, &sConfigOC, TIM_CHANNEL_2) != HAL_OK)
  {
    Error_Handler();
  }
  HAL_TIM_MspPostInit(&htim5);

}

static void MX_TIM6_Init(void)
{

  TIM_MasterConfigTypeDef sMasterConfig = {0};

  htim6.Instance = TIM6;
  htim6.Init.Prescaler = 83;
  htim6.Init.CounterMode = TIM_COUNTERMODE_UP;
  htim6.Init.Period = 999;
  if (HAL_TIM_Base_Init(&htim6) != HAL_OK)
  {
    Error_Handler();
  }
  sMasterConfig.MasterOutputTrigger = TIM_TRGO_RESET;
  sMasterConfig.MasterSlaveMode = TIM_MASTERSLAVEMODE_DISABLE;
  if (HAL_TIMEx_MasterConfigSynchronization(&htim6, &sMasterConfig) != HAL_OK)
  {
    Error_Handler();
  }

}

static void MX_TIM7_Init(void)
{

  TIM_MasterConfigTypeDef sMasterConfig = {0};

  htim7.Instance = TIM7;
  htim7.Init.Prescaler = 41;
  htim7.Init.CounterMode = TIM_COUNTERMODE_UP;
  htim7.Init.Period = 9;
  if (HAL_TIM_Base_Init(&htim7) != HAL_OK)
  {
    Error_Handler();
  }
  sMasterConfig.MasterOutputTrigger = TIM_TRGO_RESET;
  sMasterConfig.MasterSlaveMode = TIM_MASTERSLAVEMODE_DISABLE;
  if (HAL_TIMEx_MasterConfigSynchronization(&htim7, &sMasterConfig) != HAL_OK)
  {
    Error_Handler();
  }

}

static void MX_USART1_UART_Init(void)
{

  huart1.Instance = USART1;
  huart1.Init.BaudRate = 115200;
  huart1.Init.WordLength = UART_WORDLENGTH_8B;
  huart1.Init.StopBits = UART_STOPBITS_1;
  huart1.Init.Parity = UART_PARITY_NONE;
  huart1.Init.Mode = UART_MODE_TX_RX;
  huart1.Init.HwFlowCtl = UART_HWCONTROL_NONE;
  huart1.Init.OverSampling = UART_OVERSAMPLING_16;
  if (HAL_UART_Init(&huart1) != HAL_OK)
  {
    Error_Handler();
  }

}

static void MX_DMA_Init(void)
{
  /* DMA controller clock enable */
  __HAL_RCC_DMA2_CLK_ENABLE();

  /* DMA interrupt init */
  /* DMA2_Stream3_IRQn interrupt configuration */
  HAL_NVIC_SetPriority(DMA2_Stream3_IRQn, 5, 0);
  HAL_NVIC_EnableIRQ(DMA2_Stream3_IRQn);
  /* DMA2_Stream5_IRQn interrupt configuration */
  HAL_NVIC_SetPriority(DMA2_Stream5_IRQn, 7, 0);
  HAL_NVIC_EnableIRQ(DMA2_Stream5_IRQn);
  /* DMA2_Stream6_IRQn interrupt configuration */
  HAL_NVIC_SetPriority(DMA2_Stream6_IRQn, 5, 0);
  HAL_NVIC_EnableIRQ(DMA2_Stream6_IRQn);
  /* DMA2_Stream7_IRQn interrupt configuration */
  HAL_NVIC_SetPriority(DMA2_Stream7_IRQn, 7, 0);
  HAL_NVIC_EnableIRQ(DMA2_Stream7_IRQn);

}

static void MX_GPIO_Init(void)
{
  GPIO_InitTypeDef GPIO_InitStruct = {0};

  /* GPIO Ports Clock Enable */
  __HAL_RCC_GPIOE_CLK_ENABLE();
  __HAL_RCC_GPIOC_CLK_ENABLE();
  __HAL_RCC_GPIOH_CLK_ENABLE();
  __HAL_RCC_GPIOA_CLK_ENABLE();
  __HAL_RCC_GPIOB_CLK_ENABLE();
  __HAL_RCC_GPIOD_CLK_ENABLE();

  /*Configure GPIO pin Output Level */
  HAL_GPIO_WritePin(GPIOE, GPIO_PIN_2|GPIO_PIN_3|GPIO_PIN_4|GPIO_PIN_5
                          |GPIO_PIN_0|GPIO_PIN_1, GPIO_PIN_RESET);

  /*Configure GPIO pin Output Level */
  HAL_GPIO_WritePin(GPIOC, GPIO_PIN_13|GPIO_PIN_15|GPIO_PIN_0|GPIO_PIN_1
                          |GPIO_PIN_3|GPIO_PIN_4|GPIO_PIN_5|GPIO_PIN_6
                          |GPIO_PIN_7, GPIO_PIN_RESET);

  /*Configure GPIO pin Output Level */
  HAL_GPIO_WritePin(GPIOA, GPIO_PIN_2|GPIO_PIN_3|GPIO_PIN_8, GPIO_PIN_RESET);

  /*Configure GPIO pin Output Level */
  HAL_GPIO_WritePin(GPIOB, GPIO_PIN_0|GPIO_PIN_10|GPIO_PIN_11|GPIO_PIN_12
                          |GPIO_PIN_13|GPIO_PIN_7|GPIO_PIN_9, GPIO_PIN_RESET);

  /*Configure GPIO pin Output Level */
  HAL_GPIO_WritePin(GPIOD, GPIO_PIN_11|GPIO_PIN_12|GPIO_PIN_13|GPIO_PIN_6, GPIO_PIN_RESET);

  /*Configure GPIO pins : PE2 PE3 PE4 PE5
                           PE0 PE1 */
  GPIO_InitStruct.Pin = GPIO_PIN_2|GPIO_PIN_3|GPIO_PIN_4|GPIO_PIN_5
                          |GPIO_PIN_0|GPIO_PIN_1;
  GPIO_InitStruct.Mode = GPIO_MODE_OUTPUT_PP;
  GPIO_InitStruct.Pull = GPIO_NOPULL;
  GPIO_InitStruct.Speed = GPIO_SPEED_FREQ_LOW;
  HAL_GPIO_Init(GPIOE, &GPIO_InitStruct);

  /*Configure GPIO pins : PC13 PC15 PC0 PC1
                           PC3 PC4 PC5 PC6
                           PC7 */
  GPIO_InitStruct.Pin = GPIO_PIN_13|GPIO_PIN_15|GPIO_PIN_0|GPIO_PIN_1
                          |GPIO_PIN_3|GPIO_PIN_4|GPIO_PIN_5|GPIO_PIN_6
                          |GPIO_PIN_7;
  GPIO_InitStruct.Mode = GPIO_MODE_OUTPUT_PP;
  GPIO_InitStruct.Pull = GPIO_NOPULL;
  GPIO_InitStruct.Speed = GPIO_SPEED_FREQ_LOW;
  HAL_GPIO_Init(GPIOC, &GPIO_InitStruct);

  /*Configure GPIO pin : PC2 */
  GPIO_InitStruct.Pin = GPIO_PIN_2;
  GPIO_InitStruct.Mode = GPIO_MODE_INPUT;
  GPIO_InitStruct.Pull = GPIO_PULLUP;
  HAL_GPIO_Init(GPIOC, &GPIO_InitStruct);

  /*Configure GPIO pins : PA0 PA4 PA15 */
  GPIO_InitStruct.Pin = GPIO_PIN_0|GPIO_PIN_4|GPIO_PIN_15;
  GPIO_InitStruct.Mode = GPIO_MODE_INPUT;
  GPIO_InitStruct.Pull = GPIO_PULLUP;
  HAL_GPIO_Init(GPIOA, &GPIO_InitStruct);

  /*Configure GPIO pins : PA2 PA3 PA8 */
  GPIO_InitStruct.Pin = GPIO_PIN_2|GPIO_PIN_3|GPIO_PIN_8;
  GPIO_InitStruct.Mode = GPIO_MODE_OUTPUT_PP;
  GPIO_InitStruct.Pull = GPIO_NOPULL;
  GPIO_InitStruct.Speed = GPIO_SPEED_FREQ_LOW;
  HAL_GPIO_Init(GPIOA, &GPIO_InitStruct);

  /*Configure GPIO pins : PB0 PB10 PB11 PB12
                           PB13 PB7 PB9 */
  GPIO_InitStruct.Pin = GPIO_PIN_0|GPIO_PIN_10|GPIO_PIN_11|GPIO_PIN_12
                          |GPIO_PIN_13|GPIO_PIN_7|GPIO_PIN_9;
  GPIO_InitStruct.Mode = GPIO_MODE_OUTPUT_PP;
  GPIO_InitStruct.Pull = GPIO_NOPULL;
  GPIO_InitStruct.Speed = GPIO_SPEED_FREQ_LOW;
  HAL_GPIO_Init(GPIOB, &GPIO_InitStruct);

  /*Configure GPIO pins : PB1 PB2 */
  GPIO_InitStruct.Pin = GPIO_PIN_1|GPIO_PIN_2;
  GPIO_InitStruct.Mode = GPIO_MODE_INPUT;
  GPIO_InitStruct.Pull = GPIO_NOPULL;
  HAL_GPIO_Init(GPIOB, &GPIO_InitStruct);

  /*Configure GPIO pins : PD11 PD12 PD13 PD6 */
  GPIO_InitStruct.Pin = GPIO_PIN_11|GPIO_PIN_12|GPIO_PIN_13|GPIO_PIN_6;
  GPIO_InitStruct.Mode = GPIO_MODE_OUTPUT_PP;
  GPIO_InitStruct.Pull = GPIO_NOPULL;
  GPIO_InitStruct.Speed = GPIO_SPEED_FREQ_LOW;
  HAL_GPIO_Init(GPIOD, &GPIO_InitStruct);

  /*Configure GPIO pin : PD3 */
  GPIO_InitStruct.Pin = GPIO_PIN_3;
  GPIO_InitStruct.Mode = GPIO_MODE_IT_FALLING;
  GPIO_InitStruct.Pull = GPIO_PULLUP;
  HAL_GPIO_Init(GPIOD, &GPIO_InitStruct);

  /*Configure GPIO pin : PB6 */
  GPIO_InitStruct.Pin = GPIO_PIN_6;
  GPIO_InitStruct.Mode = GPIO_MODE_INPUT;
  GPIO_InitStruct.Pull = GPIO_PULLUP;
  HAL_GPIO_Init(GPIOB, &GPIO_InitStruct);

  /* EXTI interrupt init*/
  HAL_NVIC_SetPriority(EXTI3_IRQn, 5, 0);
  HAL_NVIC_EnableIRQ(EXTI3_IRQn);

}

/* FSMC initialization function */
static void MX_FSMC_Init(void)
{
  FSMC_NORSRAM_TimingTypeDef Timing;
  FSMC_NORSRAM_TimingTypeDef ExtTiming;

  /** Perform the SRAM1 memory initialization sequence
  */
  hsram1.Instance = FSMC_NORSRAM_DEVICE;
  hsram1.Extended = FSMC_NORSRAM_EXTENDED_DEVICE;
  /* hsram1.Init */
  hsram1.Init.NSBank = FSMC_NORSRAM_BANK1;
  hsram1.Init.DataAddressMux = FSMC_DATA_ADDRESS_MUX_DISABLE;
  hsram1.Init.MemoryType = FSMC_MEMORY_TYPE_SRAM;
  hsram1.Init.MemoryDataWidth = FSMC_NORSRAM_MEM_BUS_WIDTH_16;
  hsram1.Init.BurstAccessMode = FSMC_BURST_ACCESS_MODE_DISABLE;
  hsram1.Init.WaitSignalPolarity = FSMC_WAIT_SIGNAL_POLARITY_LOW;
  hsram1.Init.WrapMode = FSMC_WRAP_MODE_DISABLE;
  hsram1.Init.WaitSignalActive = FSMC_WAIT_TIMING_BEFORE_WS;
  hsram1.Init.WriteOperation = FSMC_WRITE_OPERATION_ENABLE;
  hsram1.Init.WaitSignal = FSMC_WAIT_SIGNAL_DISABLE;
  hsram1.Init.ExtendedMode = FSMC_EXTENDED_MODE_ENABLE;
  hsram1.Init.AsynchronousWait = FSMC_ASYNCHRONOUS_WAIT_DISABLE;
  hsram1.Init.WriteBurst = FSMC_WRITE_BURST_DISABLE;
  hsram1.Init.PageSize = FSMC_PAGE_SIZE_NONE;
  /* Timing */
  Timing.AddressSetupTime = 15;
  Timing.AddressHoldTime = 15;
  Timing.DataSetupTime = 60;
  Timing.BusTurnAroundDuration = 0;
  Timing.CLKDivision = 16;
  Timing.DataLatency = 17;
  Timing.AccessMode = FSMC_ACCESS_MODE_A;
  /* ExtTiming */
  ExtTiming.AddressSetupTime = 9;
  ExtTiming.AddressHoldTime = 15;
  ExtTiming.DataSetupTime = 8;
  ExtTiming.BusTurnAroundDuration = 0;
  ExtTiming.CLKDivision = 16;
  ExtTiming.DataLatency = 17;
  ExtTiming.AccessMode = FSMC_ACCESS_MODE_A;

  if (HAL_SRAM_Init(&hsram1, &Timing, &ExtTiming) != HAL_OK)
  {
    Error_Handler( );
  }

}

void InitTask_OS(void const * argument)
{
  /* init code for FATFS */
  MX_FATFS_Init();

  /* init code for USB_HOST */
  MX_USB_HOST_Init();

  /* USER CODE BEGIN 5 */
  /* Infinite loop */
  start_default_task_init();

  is_start_default_task_init = true;
  for(;;)
  {
    start_default_task_loop();
  }
  /* USER CODE END 5 */
}

void RefDataTask_OS(void const * argument)
{
  /* USER CODE BEGIN RefDataTask_OS */
  /* Infinite loop */
  for(;;)
  {
    if(!is_start_default_task_init) continue;
    ref_data_task_loop();
  }
  /* USER CODE END RefDataTask_OS */
}

void ReadUdiskTask_OS(void const * argument)
{
  /* USER CODE BEGIN ReadUdiskTask_OS */
  /* Infinite loop */
  for(;;)
  {
    if(!is_start_default_task_init) continue;
    read_udisk_task_loop();
  }
  /* USER CODE END ReadUdiskTask_OS */
}

void PrintTask_OS(void const * argument)
{
  /* USER CODE BEGIN PrintTask_OS */
  /* Infinite loop */
  for(;;)
  {
    if(!is_start_default_task_init) continue;
    print_task_loop();
  }
  /* USER CODE END PrintTask_OS */
}

void GUITask_OS(void const * argument)
{
  /* USER CODE BEGIN GUITask_OS */
  /* Infinite loop */
  for(;;)
  {
    if(!is_start_default_task_init) continue;
    gui_task_loop();
  }
  /* USER CODE END GUITask_OS */
}

void RespondGUITask_OS(void const * argument)
{
  /* USER CODE BEGIN RespondGUITask_OS */
  /* Infinite loop */
  for(;;)
  {
    if(!is_start_default_task_init) continue;
    respond_gui_task_loop();
  }
  /* USER CODE END RespondGUITask_OS */
}

void HAL_TIM_PeriodElapsedCallback(TIM_HandleTypeDef *htim)
{
  if (htim->Instance == TIM1) {
    HAL_IncTick();
  }
  /* USER CODE BEGIN Callback 1 */
  if(htim->Instance == TIM6)
  {
    TIM6_IRQHandler_process();
  }
  else if(htim->Instance == TIM4)
  {
    TIM4_IRQHandler_process();
  }
  else if(htim->Instance == TIM2)
  {
    TIM2_IRQHandler_process();
  }
//  else if(htim->Instance == TIM7)
//  {
//    TIM7_IRQHandler_process();
//  }
  /* USER CODE END Callback 1 */
}

void Error_Handler(void)
{
}

/************************ (C) COPYRIGHT STMicroelectronics *****END OF FILE****/
